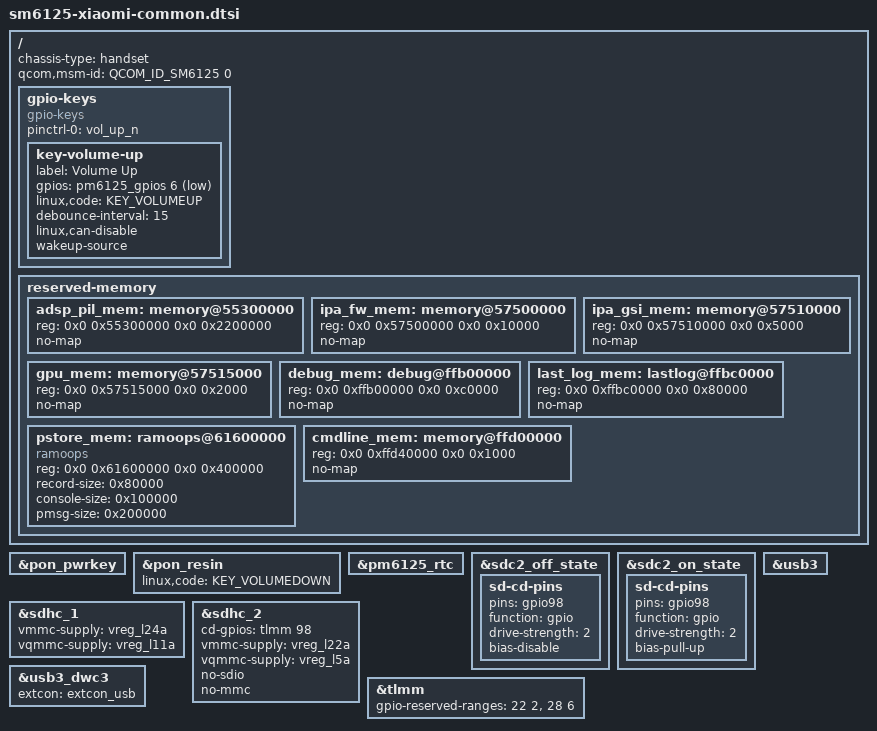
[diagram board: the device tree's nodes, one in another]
// SPDX-License-Identifier: BSD-3-Clause
/*
 * Copyright (c) 2025, Gabriel Gonzales <manigohan@disroot.org>
 */

/dts-v1/;

#include <dt-bindings/arm/qcom,ids.h>
#include <dt-bindings/gpio/gpio.h>
#include <dt-bindings/input/input.h>
#include <dt-bindings/input/gpio-keys.h>
#include <dt-bindings/pinctrl/qcom,pmic-gpio.h>
#include "sm6125.dtsi"
#include "pm6125.dtsi"

/delete-node/ &adsp_pil_mem;
/delete-node/ &ipa_fw_mem;
/delete-node/ &ipa_gsi_mem;
/delete-node/ &gpu_mem;

/ {
	chassis-type = "handset";

	qcom,msm-id = <QCOM_ID_SM6125 0>;

	gpio-keys {
		compatible = "gpio-keys";

		pinctrl-0 = <&vol_up_n>;
		pinctrl-names = "default";

		key-volume-up {
			label = "Volume Up";
			gpios = <&pm6125_gpios 6 GPIO_ACTIVE_LOW>;
			linux,code = <KEY_VOLUMEUP>;
			debounce-interval = <15>;
			linux,can-disable;
			wakeup-source;
		};
	};

	reserved-memory {
		adsp_pil_mem: memory@55300000 {
			reg = <0x0 0x55300000 0x0 0x2200000>;
			no-map;
		};

		ipa_fw_mem: memory@57500000 {
			reg = <0x0 0x57500000 0x0 0x10000>;
			no-map;
		};
		ipa_gsi_mem: memory@57510000 {
			reg = <0x0 0x57510000 0x0 0x5000>;
			no-map;
		};

		gpu_mem: memory@57515000 {
			reg = <0x0 0x57515000 0x0 0x2000>;
			no-map;
		};

		debug_mem: debug@ffb00000 {
			reg = <0x0 0xffb00000 0x0 0xc0000>;
			no-map;
		};

		last_log_mem: lastlog@ffbc0000 {
			reg = <0x0 0xffbc0000 0x0 0x80000>;
			no-map;
		};

		pstore_mem: ramoops@61600000 {
			compatible = "ramoops";
			reg = <0x0 0x61600000 0x0 0x400000>;
			record-size = <0x80000>;
			console-size = <0x100000>;
			pmsg-size = <0x200000>;
		};

		cmdline_mem: memory@ffd00000 {
			reg = <0x0 0xffd40000 0x0 0x1000>;
			no-map;
		};
	};
}

&pon_pwrkey {
	status = "okay";
};

&pon_resin {
	linux,code = <KEY_VOLUMEDOWN>;
	status = "okay";
};

&pm6125_rtc {
	status = "okay";
};

&sdc2_off_state {
	sd-cd-pins {
		pins = "gpio98";
		function = "gpio";
		drive-strength = <2>;
		bias-disable;
	};
};

&sdc2_on_state {
	sd-cd-pins {
		pins = "gpio98";
		function = "gpio";
		drive-strength = <2>;
		bias-pull-up;
	};
};

&sdhc_1 {
	vmmc-supply = <&vreg_l24a>;
	vqmmc-supply = <&vreg_l11a>;
	status = "okay";
};

&sdhc_2 {
	cd-gpios = <&tlmm 98 GPIO_ACTIVE_HIGH>;
	vmmc-supply = <&vreg_l22a>;
	vqmmc-supply = <&vreg_l5a>;
	no-sdio;
	no-mmc;
	status = "okay";
};

&tlmm {
	gpio-reserved-ranges = <22 2>, <28 6>;
};

&usb3 {
	status = "okay";
};

&usb3_dwc3 {
	extcon = <&extcon_usb>;
};
